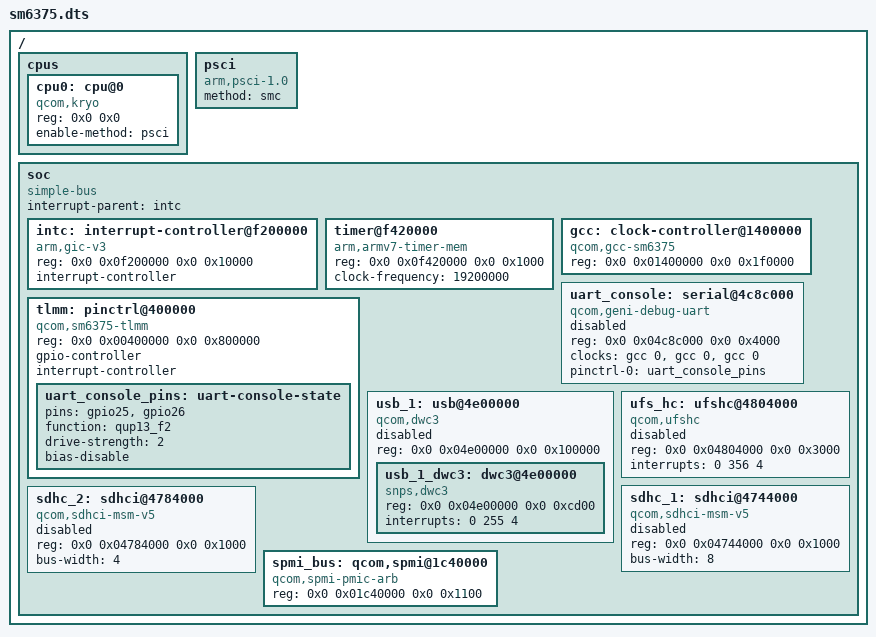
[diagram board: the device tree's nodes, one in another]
// SPDX-License-Identifier: GPL-2.0+
/*
 * Qualcomm Snapdragon 695 (SM6375) SoC Base
 */

/ {
	#address-cells = <2>;
	#size-cells = <2>;

	cpus {
		#address-cells = <2>;
		#size-cells = <0>;

		cpu0: cpu@0 {
			device_type = "cpu";
			compatible = "qcom,kryo";
			reg = <0x0 0x0>;
			enable-method = "psci";
		};
	};

	psci {
		compatible = "arm,psci-1.0";
		method = "smc";
	};

	soc {
		#address-cells = <2>;
		#size-cells = <2>;
		ranges;
		compatible = "simple-bus";
		interrupt-parent = <&intc>;

		intc: interrupt-controller@f200000 {
			compatible = "arm,gic-v3";
			reg = <0x0 0x0f200000 0x0 0x10000>;
			#interrupt-cells = <3>;
			interrupt-controller;
		};

		timer@f420000 {
			compatible = "arm,armv7-timer-mem";
			reg = <0x0 0x0f420000 0x0 0x1000>;
			clock-frequency = <19200000>;
		};

		gcc: clock-controller@1400000 {
			compatible = "qcom,gcc-sm6375";
			reg = <0x0 0x01400000 0x0 0x1f0000>;
			#clock-cells = <1>;
			#reset-cells = <1>;
			#power-domain-cells = <1>;
		};

		uart_console: serial@4c8c000 {
			compatible = "qcom,geni-debug-uart";
			reg = <0x0 0x04c8c000 0x0 0x4000>;
			reg-names = "se_phys";
			clock-names = "se-clk", "m-ahb", "s-ahb";
			clocks = <&gcc 0>, <&gcc 0>, <&gcc 0>;
			pinctrl-names = "default";
			pinctrl-0 = <&uart_console_pins>;
			status = "disabled"; /* Disabled by default, enabled by board */
		};

		tlmm: pinctrl@400000 {
			compatible = "qcom,sm6375-tlmm";
			reg = <0x0 0x00400000 0x0 0x800000>;
			gpio-controller;
			#gpio-cells = <2>;
			interrupt-controller;
			#interrupt-cells = <2>;

			uart_console_pins: uart-console-state {
				pins = "gpio25", "gpio26";
				function = "qup13_f2";
				drive-strength = <2>;
				bias-disable;
			};
		};

		usb_1: usb@4e00000 {
			compatible = "qcom,dwc3";
			reg = <0x0 0x04e00000 0x0 0x100000>;
			#address-cells = <2>;
			#size-cells = <2>;
			ranges;
			status = "disabled";

			usb_1_dwc3: dwc3@4e00000 {
				compatible = "snps,dwc3";
				reg = <0x0 0x04e00000 0x0 0xcd00>;
				interrupts = <0 255 4>;
			};
		};

		ufs_hc: ufshc@4804000 {
			compatible = "qcom,ufshc";
			reg = <0x0 0x04804000 0x0 0x3000>;
			interrupts = <0 356 4>;
			status = "disabled";
		};

		sdhc_1: sdhci@4744000 {
			compatible = "qcom,sdhci-msm-v5";
			reg = <0x0 0x04744000 0x0 0x1000>;
			bus-width = <8>;
			status = "disabled";
		};

		sdhc_2: sdhci@4784000 {
			compatible = "qcom,sdhci-msm-v5";
			reg = <0x0 0x04784000 0x0 0x1000>;
			bus-width = <4>;
			status = "disabled";
		};

		spmi_bus: qcom,spmi@1c40000 {
			compatible = "qcom,spmi-pmic-arb";
			reg = <0x0 0x01c40000 0x0 0x1100>;
			#address-cells = <1>;
			#size-cells = <0>;
		};
	};
};
